# ATmega8535 register map
Vendor: Atmel; File version: 1.0
CPU: other r0p0, little endian, no MPU, no FPU, 4 interrupt priority bits
Registers are 8-bit, read-write, reset 0x0 unless marked. A register's access mark holds for its fields unless they carry their own. Offsets are from the block's base; lines under a group give offsets from that group; [hi:lo] are bit positions; {n}, {i} and the like mark numbered series; 'fields as' and 'values as' point back to an identical list; <NAME> marks a mode.

## Memory map
0x00800020 TWI blocks up to offset 0x37 — Two Wire Serial Interface
0x00800024 ADC blocks up to offset 0x2D — Analog-to-Digital Converter
0x00800028 AC size 0x1 — Analog Comparator
0x00800029 USART blocks up to offset 0x18
0x0080002D SPI size 0x3 — Serial Peripheral Interface
0x00800030 PORTD size 0x3 — I/O Port
0x00800033 PORTC size 0x3 — I/O Port
0x00800036 PORTB size 0x3 — I/O Port
0x00800039 PORTA size 0x3 — I/O Port
0x0080003C EEPROM size 0x4
0x00800041 WDT size 0x1 — Watchdog Timer
0x00800042 TC2 blocks up to offset 0x18 — Timer/Counter, 8-bit Async
0x00800046 TC1 blocks up to offset 0x14 — Timer/Counter, 16-bit
0x00800050 CPU blocks up to offset 0x10 — CPU Registers
0x00800050 TC0 blocks up to offset 0xD — Timer/Counter, 8-bit
0x00800054 EXINT blocks up to offset 0x8 — External Interrupts

## Interrupts
0 RESET (CPU) — External Reset, Power-on Reset and Watchdog Reset
1 INT0 (CPU) — External Interrupt 0
2 INT1 (CPU) — External Interrupt 1
3 TIMER2_COMP (CPU) — Timer/Counter2 Compare Match
4 TIMER2_OVF (CPU) — Timer/Counter2 Overflow
5 TIMER1_CAPT (CPU) — Timer/Counter1 Capture Event
6 TIMER1_COMPA (CPU) — Timer/Counter1 Compare Match A
7 TIMER1_COMPB (CPU) — Timer/Counter1 Compare Match B
8 TIMER1_OVF (CPU) — Timer/Counter1 Overflow
9 TIMER0_OVF (CPU) — Timer/Counter0 Overflow
10 SPI_STC (CPU) — SPI Serial Transfer Complete
11 USART_RX (CPU) — USART, RX Complete
12 USART_UDRE (CPU) — USART Data Register Empty
13 USART_TX (CPU) — USART, TX Complete
14 ADC (CPU) — ADC Conversion Complete
15 EE_RDY (CPU) — EEPROM Ready
16 ANA_COMP (CPU) — Analog Comparator
17 TWI (CPU) — Two-wire Serial Interface
18 INT2 (CPU) — External Interrupt Request 2
19 TIMER0_COMP (CPU) — TimerCounter0 Compare Match
20 SPM_RDY (CPU) — Store Program Memory Read

## AC — Analog Comparator
Base 0x00800028
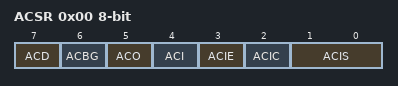
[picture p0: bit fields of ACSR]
0x00 ACSR — Analog Comparator Control And Status Register (read-only for debugger)
  [7] ACD — Analog Comparator Disable
  [6] ACBG — Analog Comparator Bandgap Select
  [5] ACO — Analog Compare Output
  [4] ACI — Analog Comparator Interrupt Flag
  [3] ACIE — Analog Comparator Interrupt Enable
  [2] ACIC — Analog Comparator Input Capture Enable
  [1:0] ACIS — Analog Comparator Interrupt Mode Select bits
    0=INTERRUPT_ON_TOGGLE; 2=INTERRUPT_ON_FALLING_EDGE; 3=INTERRUPT_ON_RISING_EDGE

## ADC — Analog-to-Digital Converter
Base 0x00800024
0x00 ADC 16-bit (reset mask 0xFF) — ADC Data Register Bytes
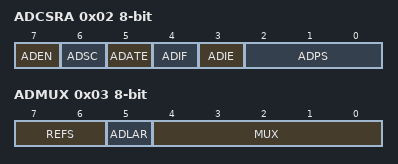
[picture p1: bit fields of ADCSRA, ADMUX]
0x02 ADCSRA — The ADC Control and Status register (read-only for debugger)
  [7] ADEN — ADC Enable
  [6] ADSC — ADC Start Conversion
  [5] ADATE — ADC Auto Trigger
  [4] ADIF — ADC Interrupt Flag
  [3] ADIE — ADC Interrupt Enable
  [2:0] ADPS — ADC Prescaler Select Bits
    1=2; 2=4; 3=8; 4=16; 5=32; 6=64; 7=128
0x03 ADMUX — The ADC multiplexer Selection Register
  [7:6] REFS — Reference Selection Bits
    0=AREF_INTERNAL_VREF_TURNED_OFF; 1=AVCC_WITH_EXTERNAL_CAPACITOR_AT_AREF_PIN; 3=INTERNAL_2_56V_VOLTAGE_REFERENCE_WITH_EXTERNAL_CAPACITOR_AT_AREF_PIN
  [5] ADLAR — Left Adjust Result
  [4:0] MUX — Analog Channel and Gain Selection Bits
0x2C SFIOR — Special Function IO Register
  [7:5] ADTS — ADC Auto Trigger Sources

## CPU — CPU Registers
Base 0x00800050
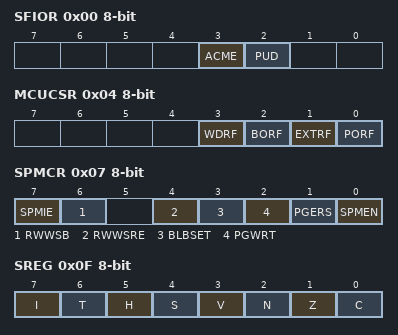
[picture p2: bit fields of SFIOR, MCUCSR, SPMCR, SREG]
0x00 SFIOR — Special Function IO Register
  [3] ACME — Analog Comparator Multiplexer Enable
  [2] PUD — Pull-up Disable
0x01 OSCCAL — Oscillator Calibration Value
  [7:0] OSCCAL — Oscillator Calibration
0x04 MCUCSR — MCU Control And Status Register
  [3] WDRF — Watchdog Reset Flag
  [2] BORF — Brown-out Reset Flag
  [1] EXTRF — External Reset Flag
  [0] PORF — Power-on reset flag
0x05 MCUCR — MCU Control Register
  [6] SE — Sleep Enable
  [7:4] SM — Sleep Mode Select
    0=IDLE; 1=ADC (ADC Noise Reduction (If Available)); 2=PDOWN (Power Down); 3=PSAVE (Power Save); 10=STDBY (Standby); 11=ESTDBY (Extended Standby)
  [3:2] ISC1 — Interrupt Sense Control 1 Bits
  [1:0] ISC0 — Interrupt Sense Control 0 Bits
0x07 SPMCR
  [7] SPMIE — SPM Interrupt Enable
  [6] RWWSB — Read-While-Write Section Busy
  [4] RWWSRE — Read-While-Write Section Read Enable
  [3] BLBSET — Boot Lock Bit Set
  [2] PGWRT — Page Write
  [1] PGERS — Page Erase
  [0] SPMEN — Store Program Memory Enable
0x0D SP 16-bit (reset mask 0xFF) — Stack Pointer
0x0F SREG — Status Register
  [7] I — Global Interrupt Enable
  [6] T — Bit Copy Storage
  [5] H — Half Carry Flag
  [4] S — Sign Bit
  [3] V — Two's Complement Overflow Flag
  [2] N — Negative Flag
  [1] Z — Zero Flag
  [0] C — Carry Flag
